# ESP32-C3 register map
Vendor: ESPRESSIF SYSTEMS (SHANGHAI) CO., LTD.; Series: ESP32 C-Series; File version: 19
CPU: RV32IMC r0p0, little endian, no MPU, no FPU, 0 interrupt priority bits
Address unit: 32 bits
Registers are 32-bit, read-write, reset 0x0 unless marked. A register's access mark holds for its fields unless they carry their own. Offsets are from the block's base; [hi:lo] are bit positions; lines under a group give offsets from that group; {n}, {i} and the like mark numbered series.

## WIFI — MAC controller for Wi-Fi peripheral
Base 0x60033000
{0x0+0x40*i} FILTER_BANK{i} (i=0..1) group — Filter banks for frame reception. Bank zero is for the BSSID and bank one for the RA. Each filter bank has registers for four interfaces.
  {0x0+8j} ADDR_LOW{j} (j=0..3) — First 4 bytes of BSSID MAC address filter
  {0x4+8j} ADDR_HIGH{j} (j=0..3) — last 2 bytes of BSSID MAC address filter
    [15:0] ADDR
  {0x20+8j} MASK_LOW{j} (j=0..3) — First 4 bytes of BSSID MAC address filter mask
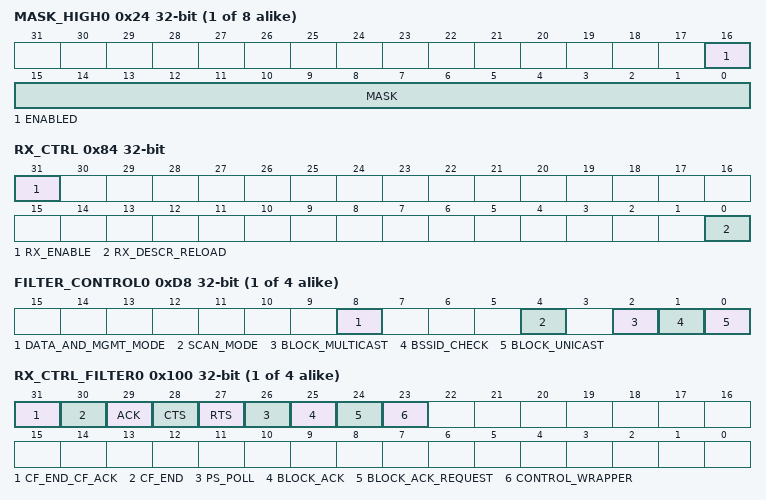
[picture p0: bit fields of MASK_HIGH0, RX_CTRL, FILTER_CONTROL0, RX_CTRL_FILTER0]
  {0x24+8j} MASK_HIGH{j} (j=0..3) — last 2 bytes of BSSID MAC address filter mask
    [16] ENABLED, [15:0] MASK
0x84 RX_CTRL — Controls the reception of frames
  [31] RX_ENABLE — Enable frame reception
  [0] RX_DESCR_RELOAD — Instruct the hardware to reload the RX descriptors
0x88 RX_DMA_LIST group
  0x00 RX_DESCR_BASE access not given — base address of the RX DMA list
  0x04 RX_DESCR_NEXT — next item in the RX DMA list
  0x08 RX_DESCR_LAST — last item in RX DMA list
{0xD8+4i} FILTER_CONTROL{i} (i=0..3) — Controls the RX filter for an interface
  [8] DATA_AND_MGMT_MODE — Receive everything except control frames
  [4] SCAN_MODE — Receive beacon frames
  [2] BLOCK_MULTICAST — Block multicast frames not matching the address filter
  [1] BSSID_CHECK — Check BSSID for filtering
  [0] BLOCK_UNICAST — Block unicast frames not matching the address filter
{0x100+4i} RX_CTRL_FILTER{i} (i=0..3) — Configures which control frames pass the RX filter. Setting a bit lets that frame type pass the filter.
  [31] CF_END_CF_ACK — Filter CF-End+CF-Ack frames
  [30] CF_END — Filter CF-End frames
  [29] ACK — Filter ACK frames
  [28] CTS — Filter CTS frames
  [27] RTS — Filter RTS frames
  [26] PS_POLL — Filter PS-Poll frames
  [25] BLOCK_ACK — Filter Block ACK frames
  [24] BLOCK_ACK_REQUEST — Filter Block ACK Request frames
  [23] CONTROL_WRAPPER — Filter Control Wrapper frames
0x800 CRYPTO_CONTROL group — Control registers for hardware crypto
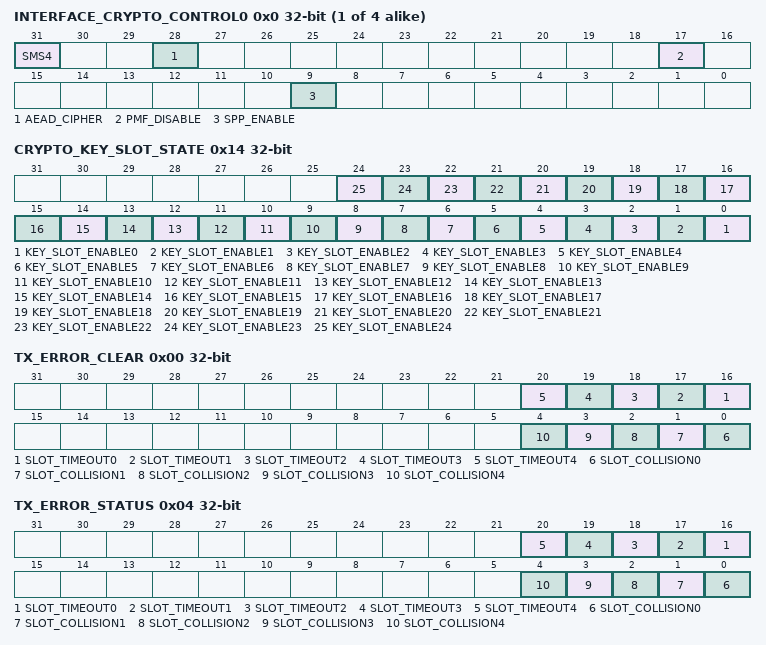
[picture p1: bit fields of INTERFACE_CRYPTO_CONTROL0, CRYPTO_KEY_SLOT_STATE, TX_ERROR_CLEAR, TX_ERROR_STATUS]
  {0x0+4j} INTERFACE_CRYPTO_CONTROL{j} (j=0..3) — Control over cryptographic parameters for a specific interface
    [31] SMS4 — Cipher is SMS4
    [28] AEAD_CIPHER — Does the cipher employ Authenticated Encryption with Associated Data (AEAD)
    [17] PMF_DISABLE — Disable Protected Management Frames (PMF)
    [9] SPP_ENABLE — Enable Signaling and Payload Protection (SPP) for A-MSDUs
  0x10 GENERAL_CRYPTO_CONTROL — Control over the whole crypto unit
  0x14 CRYPTO_KEY_SLOT_STATE — State of cryptographic key slots
    [n] KEY_SLOT_ENABLE{n} (n=0..24) — Enable the key slot corresponding to this bit
0xC3C MAC_INTERRUPT group — Status and clear for the WIFI_MAC interrupt
  0x00 WIFI_INT_STATUS access not given — Interrupt status of WIFI peripheral
  0x04 WIFI_INT_CLEAR access not given — Interrupt status clear of WIFI peripheral
0xCA0 CTRL — Exact name and meaning unknown, used for initializing the MAC
0xCA4 TXQ_STATE group — State of transmission queues
  0x00 TX_ERROR_CLEAR access not given — Clear the error status of a slot
    [n+16] SLOT_TIMEOUT{n} (n=0..4) — Timeout clear bit for a slot
    [n] SLOT_COLLISION{n} (n=0..4) — Collision clear bit for a slot
  0x04 TX_ERROR_STATUS access not given — Error status of a slot
    [n+16] SLOT_TIMEOUT{n} (n=0..4) — Timeout status bit for a slot
    [n] SLOT_COLLISION{n} (n=0..4) — Collision status bit for a slot
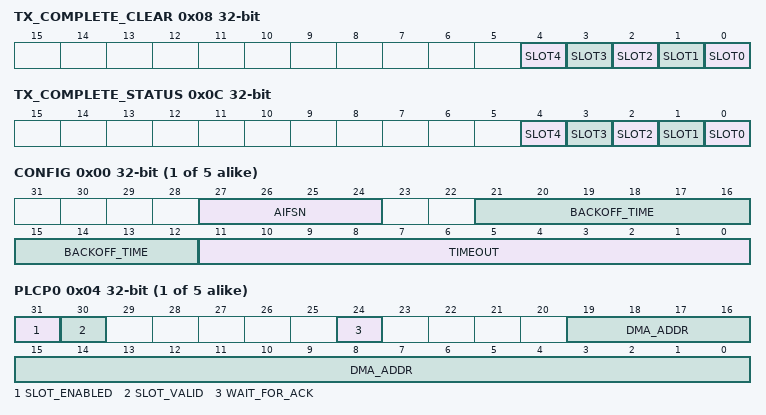
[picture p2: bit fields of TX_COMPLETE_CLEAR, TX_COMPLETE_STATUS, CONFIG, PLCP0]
  0x08 TX_COMPLETE_CLEAR access not given — Clear the completion status of a slot
    [n] SLOT{n} (n=0..4) — Clear bit for a slot
  0x0C TX_COMPLETE_STATUS access not given — Completion status of a slot
    [n] SLOT{n} (n=0..4) — Status bit for a slot
{0xCE4+8i} TX_SLOT_CONFIG{i} (i=0..4) group — Used to configure the TX slot.
  0x00 CONFIG
    [27:24] AIFSN, [21:12] BACKOFF_TIME, [11:0] TIMEOUT
  0x04 PLCP0
    [31] SLOT_ENABLED — Marks this slot as ready for transmission
    [30] SLOT_VALID — Marks this slot as valid
    [24] WAIT_FOR_ACK — Enables ACK timeouts
    [19:0] DMA_ADDR — Bottom bits of address of dma_item
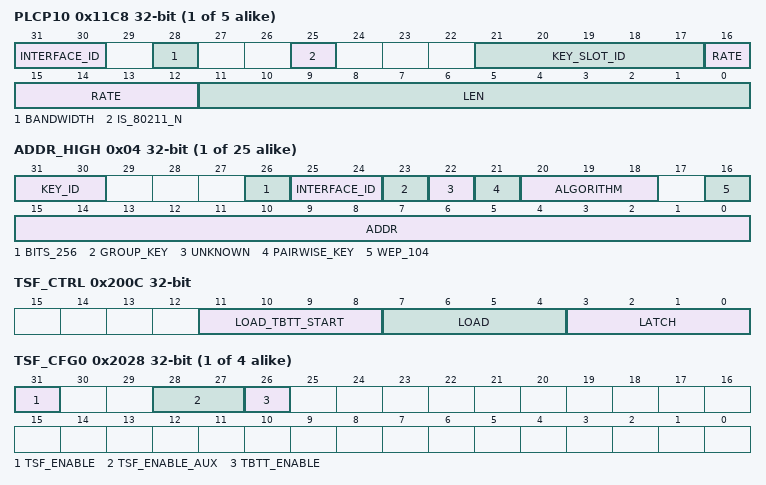
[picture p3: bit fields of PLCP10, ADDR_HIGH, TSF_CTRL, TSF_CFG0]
{0x11C8+0x4C*i} PLCP1{i} (i=0..4)
  [31:30] INTERFACE_ID — ID of the interface this transmission is from
  [28] BANDWIDTH — Zero indicates 20MHz and one indicates 40MHz
  [25] IS_80211_N — Bit indicating if this is 802.11n
  [21:17] KEY_SLOT_ID — Key slot to use for encryption
  [16:12] RATE — Packet rate (see wifi_phy_rate_t)
  [11:0] LEN — Length of packet (in bytes)
{0x11CC+0x4C*i} TX_PTI{i} (i=0..4) — Coexistence priorities of the TX slot, written by hal_set_tx_pti
{0x11D0+0x4C*i} HT_SIG{i} (i=0..4) — HT-SIG field in HT preamble
{0x11E0+0x4C*i} HT_UNKNOWN{i} (i=0..4) — exact meaning and name unknown, related to HT
  [19:0] LENGTH — The length of the PPDU
{0x11E4+0x4C*i} PLCP2{i} (i=0..4)
  [5] UNKNOWN — meaning unknown, set to one for TX
{0x11E8+0x4C*i} DURATION{i} (i=0..4) — duration of the frame exchange
{0x11F0+0x4C*i} PMD{i} (i=0..4) — TX result of the slot, read by hal_mac_get_txq_pmd
{0x1400+0x28*i} CRYPTO_KEY_SLOT{i} (i=0..24) group — Cryptographic keys for MPDU encapsulation and decapsulation
  0x00 ADDR_LOW — Lower four octets of the MAC address
  0x04 ADDR_HIGH — Higher two octets of the MAC address and config bits
    [31:30] KEY_ID — Protocol identifier of the key
    [26] BITS_256 — Key length is 256 bits
    [25:24] INTERFACE_ID — Index of the interface using the key
    [23] GROUP_KEY — Is this a group key
    [22] UNKNOWN — Meaning unknown set to 1 for all algorithms
    [21] PAIRWISE_KEY — Is this a pairwise key
    [20:18] ALGORITHM — In use algorithm
    [16] WEP_104 — Is the cipher WEP104
    [15:0] ADDR — Higher two octets of the MAC address
  {0x8+4j} KEY_VALUE{j} (j=0..7) — Actual key data
0x2000 MAC_TIME access not given — Current value of the MAC timer
0x200C TSF_CTRL — Control for the per-interface TSF counters. Written by tsf_hal_get_counter_value, tsf_hal_set_counter_value and tsf_hal_set_tbtt_start_time.
  [11:8] LOAD_TBTT_START — Bit n loads the TBTT start time of interface n from TBTT_START.
  [7:4] LOAD — Bit n loads the TSF counter of interface n from TSF_LOAD.
  [3:0] LATCH — Bit n latches the TSF counter of interface n into TSF_TIME for reading. Cleared again after the read.
0x2010 TSF_LOAD_LOW — Low word of the value loaded into a TSF counter
0x2014 TSF_LOAD_HIGH — High word of the value loaded into a TSF counter
0x2018 TSF_TIME_LOW access not given — Low word of the latched TSF counter
0x201C TSF_TIME_HIGH access not given — High word of the latched TSF counter
0x2020 TBTT_START — TBTT start time, loaded into an interface with TSF_CTRL.LOAD_TBTT_START
  [25:0] START_TIME
{0x2028+0xC*i} TSF_CFG{i} (i=0..3) — TSF and TBTT configuration of an interface
  [31] TSF_ENABLE — Enables the TSF counter, checked by tsf_hal_is_tsf_enabled
  [28:27] TSF_ENABLE_AUX — Bits 27 and 28 are set together with TSF_ENABLE by tsf_hal_set_tsf_enable, meaning unknown
  [26] TBTT_ENABLE — Set by tsf_hal_set_tbtt_enable
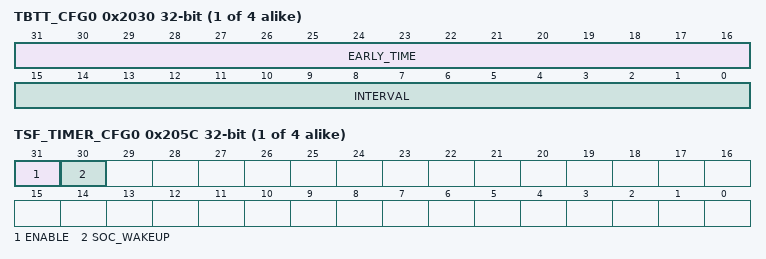
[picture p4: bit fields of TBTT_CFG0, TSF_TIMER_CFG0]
{0x2030+0xC*i} TBTT_CFG{i} (i=0..3) — TBTT interval and early time of an interface
  [31:16] EARLY_TIME — How much earlier than the TBTT the interrupt fires, set by tsf_hal_set_tbtt_early_time
  [15:0] INTERVAL — Beacon interval in TUs (the blob shifts microseconds right by 10)
{0x205C+8i} TSF_TIMER_CFG{i} (i=0..3) — Configuration of a TSF timer
  [31] ENABLE — Set by tsf_hal_set_timer_enable
  [30] SOC_WAKEUP — Wake the SoC when the timer fires, set by tsf_hal_set_timer_soc_wakeup_enable
{0x2060+8i} TSF_TIMER_TARGET{i} (i=0..3) — Target of a TSF timer, written by tsf_hal_set_timer_target
0x2110 PWR_INT_ENABLE — Interrupt enable for the WIFI_PWR interrupt. TBTT of interface n is bit (4 - n), TSF timer n is bit (8 - n).
0x2118 PWR_INTERRUPT group — Status and clear for the WIFI_PWR interrupt
  0x00 PWR_INT_STATUS access not given — Interrupt status for the WIFI_PWR interrupt
  0x04 PWR_INT_CLEAR access not given — Interrupt status clear for the WIFI_PWR interrupt
